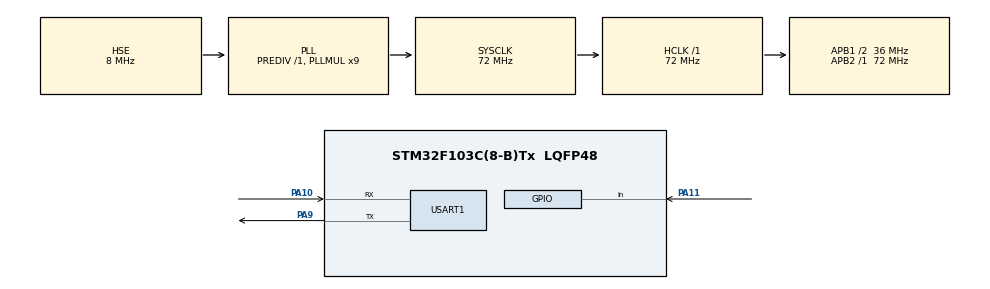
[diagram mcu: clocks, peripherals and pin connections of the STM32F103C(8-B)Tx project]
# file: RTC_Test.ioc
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Mcu.Family=STM32F1
Mcu.Name=STM32F103C(8-B)Tx
Mcu.Package=LQFP48
NVIC.PriorityGroup=NVIC_PRIORITYGROUP_4
PA10.Mode=Asynchronous
PA10.Signal=USART1_RX
PA11.GPIO_PuPd=GPIO_PULLUP
PA11.Signal=GPIO_Input
PA13.Mode=Serial_Wire
PA13.Signal=SYS_JTMS-SWDIO
PA14.Mode=Serial_Wire
PA14.Signal=SYS_JTCK-SWCLK
PA9.Mode=Asynchronous
PA9.Signal=USART1_TX
PC14-OSC32_IN.Mode=LSE-External-Oscillator
PC14-OSC32_IN.Signal=RCC_OSC32_IN
PC15-OSC32_OUT.Mode=LSE-External-Oscillator
PC15-OSC32_OUT.Signal=RCC_OSC32_OUT
PD0-OSC_IN.Mode=HSE-External-Oscillator
PD0-OSC_IN.Signal=RCC_OSC_IN
PD1-OSC_OUT.Mode=HSE-External-Oscillator
PD1-OSC_OUT.Signal=RCC_OSC_OUT
ProjectManager.HeapSize=0x200
ProjectManager.StackSize=0x400
ProjectManager.TargetToolchain=MDK-ARM V5.27
RCC.AHBFreq_Value=72000000
RCC.APB1CLKDivider=RCC_HCLK_DIV2
RCC.APB1Freq_Value=36000000
RCC.APB1TimFreq_Value=72000000
RCC.APB2Freq_Value=72000000
RCC.APB2TimFreq_Value=72000000
RCC.HCLKFreq_Value=72000000
RCC.PLLMUL=RCC_PLL_MUL9
RCC.PLLSourceVirtual=RCC_PLLSOURCE_HSE
RCC.RTCClockSelection=RCC_RTCCLKSOURCE_LSE
RCC.SYSCLKFreq_VALUE=72000000
RCC.SYSCLKSource=RCC_SYSCLKSOURCE_PLLCLK
RCC.USBFreq_Value=72000000
RTC.Format=RTC_FORMAT_BIN
USART1.VirtualMode=VM_ASYNC
VP_RTC_VS_RTC_Activate.Mode=RTC_Enabled
VP_RTC_VS_RTC_Calendar.Mode=RTC_Calendar
board=custom

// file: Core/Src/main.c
/* USER CODE BEGIN Header */
/**
  ******************************************************************************
  * @file           : main.c
  * @brief          : Main program body
  ******************************************************************************
  * @attention
  *
  * <h2><center>&copy; Copyright (c) 2020 STMicroelectronics.
  * All rights reserved.</center></h2>
  *
  * This software component is licensed by ST under BSD 3-Clause license,
  * the "License"; You may not use this file except in compliance with the
  * License. You may obtain a copy of the License at:
  *                        opensource.org/licenses/BSD-3-Clause
  *
  ******************************************************************************
  */
/* USER CODE END Header */
#include "main.h"

/* USER CODE BEGIN Includes */
#include "stdio.h"
#include "string.h"
/* USER CODE END Includes */

RTC_HandleTypeDef hrtc;

UART_HandleTypeDef huart1;

void SystemClock_Config(void);
static void MX_GPIO_Init(void);
static void MX_RTC_Init(void);
static void MX_USART1_UART_Init(void);

int main(void)
{
  /* USER CODE BEGIN 1 */
	RTC_DateTypeDef Date;
	RTC_TimeTypeDef Time;

	RTC_TimeTypeDef sTime = {0};
  RTC_DateTypeDef DateToUpdate = {0};

	uint8_t Buf[64];
  /* USER CODE END 1 */

  /* MCU Configuration--------------------------------------------------------*/

  /* Reset of all peripherals, Initializes the Flash interface and the Systick. */
  HAL_Init();

  /* Configure the system clock */
  SystemClock_Config();

  /* USER CODE BEGIN SysInit */
	HAL_Delay(100);
  /* USER CODE END SysInit */

  /* Initialize all configured peripherals */
  MX_GPIO_Init();
  MX_RTC_Init();
  MX_USART1_UART_Init();

  /* Infinite loop */
  /* USER CODE BEGIN WHILE */
  while (1)
  {
		HAL_RTC_GetTime(&hrtc,&Time,FORMAT_BIN);
		HAL_RTC_GetDate(&hrtc,&Date,FORMAT_BIN);
		sprintf((char*)Buf,"20%02d/%02d/%02d %02d:%02d:%02d\r\n",Date.Year,Date.Month,Date.Date,Time.Hours,Time.Minutes,Time.Seconds);
		HAL_UART_Transmit(&huart1,Buf,strlen((char*)Buf),100);
		HAL_Delay(1000);
    /* USER CODE END WHILE */

    /* USER CODE BEGIN 3 */
		if(HAL_GPIO_ReadPin(GPIOA,GPIO_PIN_11)==GPIO_PIN_RESET)
		{
			sTime.Hours = 0;
			sTime.Minutes = 0;
			sTime.Seconds = 0;

			if (HAL_RTC_SetTime(&hrtc, &sTime, RTC_FORMAT_BIN) != HAL_OK)
			{
				Error_Handler();
			}
			DateToUpdate.WeekDay = RTC_WEEKDAY_MONDAY;
			DateToUpdate.Month = RTC_MONTH_JANUARY;
			DateToUpdate.Date = 1;
			DateToUpdate.Year = 0;

			if (HAL_RTC_SetDate(&hrtc, &DateToUpdate, RTC_FORMAT_BIN) != HAL_OK)
			{
				Error_Handler();
			}
		}
  }
  /* USER CODE END 3 */
}

void SystemClock_Config(void)
{
  RCC_OscInitTypeDef RCC_OscInitStruct = {0};
  RCC_ClkInitTypeDef RCC_ClkInitStruct = {0};
  RCC_PeriphCLKInitTypeDef PeriphClkInit = {0};

  /** Initializes the RCC Oscillators according to the specified parameters
  * in the RCC_OscInitTypeDef structure.
  */
  RCC_OscInitStruct.OscillatorType = RCC_OSCILLATORTYPE_HSE|RCC_OSCILLATORTYPE_LSE;
  RCC_OscInitStruct.HSEState = RCC_HSE_ON;
  RCC_OscInitStruct.HSEPredivValue = RCC_HSE_PREDIV_DIV1;
  RCC_OscInitStruct.LSEState = RCC_LSE_ON;
  RCC_OscInitStruct.HSIState = RCC_HSI_ON;
  RCC_OscInitStruct.PLL.PLLState = RCC_PLL_ON;
  RCC_OscInitStruct.PLL.PLLSource = RCC_PLLSOURCE_HSE;
  RCC_OscInitStruct.PLL.PLLMUL = RCC_PLL_MUL9;
  if (HAL_RCC_OscConfig(&RCC_OscInitStruct) != HAL_OK)
  {
    Error_Handler();
  }
  /** Initializes the CPU, AHB and APB buses clocks
  */
  RCC_ClkInitStruct.ClockType = RCC_CLOCKTYPE_HCLK|RCC_CLOCKTYPE_SYSCLK
                              |RCC_CLOCKTYPE_PCLK1|RCC_CLOCKTYPE_PCLK2;
  RCC_ClkInitStruct.SYSCLKSource = RCC_SYSCLKSOURCE_PLLCLK;
  RCC_ClkInitStruct.AHBCLKDivider = RCC_SYSCLK_DIV1;
  RCC_ClkInitStruct.APB1CLKDivider = RCC_HCLK_DIV2;
  RCC_ClkInitStruct.APB2CLKDivider = RCC_HCLK_DIV1;

  if (HAL_RCC_ClockConfig(&RCC_ClkInitStruct, FLASH_LATENCY_2) != HAL_OK)
  {
    Error_Handler();
  }
  PeriphClkInit.PeriphClockSelection = RCC_PERIPHCLK_RTC;
  PeriphClkInit.RTCClockSelection = RCC_RTCCLKSOURCE_LSE;
  if (HAL_RCCEx_PeriphCLKConfig(&PeriphClkInit) != HAL_OK)
  {
    Error_Handler();
  }
}

static void MX_RTC_Init(void)
{

  RTC_TimeTypeDef sTime = {0};
  RTC_DateTypeDef DateToUpdate = {0};

  /** Initialize RTC Only
  */
  hrtc.Instance = RTC;
  hrtc.Init.AsynchPrediv = RTC_AUTO_1_SECOND;
  hrtc.Init.OutPut = RTC_OUTPUTSOURCE_ALARM;
  if (HAL_RTC_Init(&hrtc) != HAL_OK)
  {
    Error_Handler();
  }

  /** Initialize RTC and set the Time and Date
  */
  sTime.Hours = 0;
  sTime.Minutes = 0;
  sTime.Seconds = 0;

  if (HAL_RTC_SetTime(&hrtc, &sTime, RTC_FORMAT_BIN) != HAL_OK)
  {
    Error_Handler();
  }
  DateToUpdate.WeekDay = RTC_WEEKDAY_MONDAY;
  DateToUpdate.Month = RTC_MONTH_JANUARY;
  DateToUpdate.Date = 1;
  DateToUpdate.Year = 0;

  if (HAL_RTC_SetDate(&hrtc, &DateToUpdate, RTC_FORMAT_BIN) != HAL_OK)
  {
    Error_Handler();
  }

}

static void MX_USART1_UART_Init(void)
{

  huart1.Instance = USART1;
  huart1.Init.BaudRate = 115200;
  huart1.Init.WordLength = UART_WORDLENGTH_8B;
  huart1.Init.StopBits = UART_STOPBITS_1;
  huart1.Init.Parity = UART_PARITY_NONE;
  huart1.Init.Mode = UART_MODE_TX_RX;
  huart1.Init.HwFlowCtl = UART_HWCONTROL_NONE;
  huart1.Init.OverSampling = UART_OVERSAMPLING_16;
  if (HAL_UART_Init(&huart1) != HAL_OK)
  {
    Error_Handler();
  }

}

static void MX_GPIO_Init(void)
{
  GPIO_InitTypeDef GPIO_InitStruct = {0};

  /* GPIO Ports Clock Enable */
  __HAL_RCC_GPIOC_CLK_ENABLE();
  __HAL_RCC_GPIOD_CLK_ENABLE();
  __HAL_RCC_GPIOA_CLK_ENABLE();

  /*Configure GPIO pin : PA11 */
  GPIO_InitStruct.Pin = GPIO_PIN_11;
  GPIO_InitStruct.Mode = GPIO_MODE_INPUT;
  GPIO_InitStruct.Pull = GPIO_PULLUP;
  HAL_GPIO_Init(GPIOA, &GPIO_InitStruct);

}

void Error_Handler(void)
{
}

/************************ (C) COPYRIGHT STMicroelectronics *****END OF FILE****/
